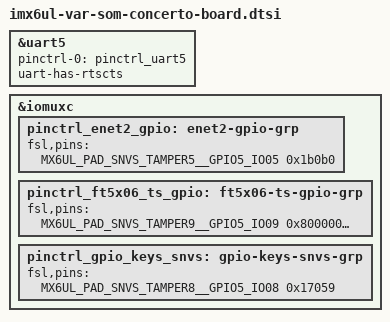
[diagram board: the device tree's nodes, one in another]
// SPDX-License-Identifier: GPL-2.0+
/*
 * Variscite Concerto carrier board for VAR-SOM-6UL
 *
 * Link: https://variscite.com/carrier-boards/concerto-board/
 *
 * Copyright (C) 2026 Variscite Ltd. - https://www.variscite.com
 */

#include "imx6ul-imx6ull-var-som-concerto-board.dtsi"

/* ttymxc4 UART */
&uart5 {
	pinctrl-names = "default";
	pinctrl-0 = <&pinctrl_uart5>;
	uart-has-rtscts;
	status = "okay";
};

&iomuxc {
	pinctrl_enet2_gpio: enet2-gpio-grp {
		fsl,pins = <
			MX6UL_PAD_SNVS_TAMPER5__GPIO5_IO05	0x1b0b0
		>;
	};

	pinctrl_ft5x06_ts_gpio: ft5x06-ts-gpio-grp {
		fsl,pins = <
			MX6UL_PAD_SNVS_TAMPER9__GPIO5_IO09	0x80000000
		>;
	};

	pinctrl_gpio_keys_snvs: gpio-keys-snvs-grp {
		fsl,pins = <
			MX6UL_PAD_SNVS_TAMPER8__GPIO5_IO08	0x17059
		>;
	};
};
